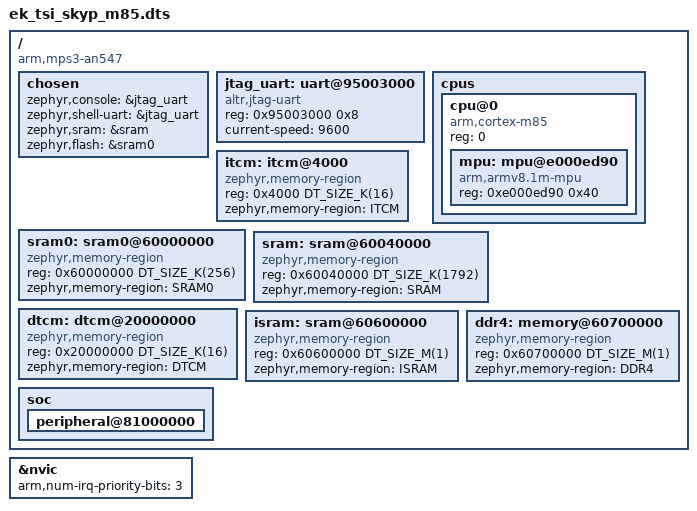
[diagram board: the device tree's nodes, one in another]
/*
 * Copyright (c) 2024 TSI
 * Copyright 2022 Arm Limited and/or its affiliates <open-source-office@arm.com>
 *
 * SPDX-License-Identifier: Apache-2.0
 */

/dts-v1/;

#include <arm/armv8.1-m.dtsi>
#include <zephyr/dt-bindings/i2c/i2c.h>
#include <zephyr/dt-bindings/input/input-event-codes.h>
#include <mem.h>

/ {
	compatible = "arm,mps3-an547";
	#address-cells = <1>;
	#size-cells = <1>;

	chosen {
		zephyr,console = &jtag_uart;
		/*
		zephyr,console = &uart0;
		*/
		zephyr,shell-uart = &jtag_uart;
		/*
		zephyr,shell-uart = &uart0;
		*/
		zephyr,sram = &sram;
		zephyr,flash = &sram0;
	};

        jtag_uart: uart@95003000 {
                compatible = "altr,jtag-uart";
                reg = <0x95003000 0x8>;
                status = "enabled";
        };

	cpus {
		#address-cells = <1>;
		#size-cells = <0>;

		cpu@0 {
			device_type = "cpu";
			compatible = "arm,cortex-m85";
			reg = <0>;
			#address-cells = <1>;
			#size-cells = <1>;

			mpu: mpu@e000ed90 {
				compatible = "arm,armv8.1m-mpu";
				reg = <0xe000ed90 0x40>;
			};
		};
	};

	/* We utilize the secure addresses, if you subtract 0x10000000
	 * you'll get the non-secure alias
	 */
        itcm: itcm@4000 {   /* alias @ 0x4000 */
                compatible = "zephyr,memory-region";
                reg = <0x4000 DT_SIZE_K(16)>;
                zephyr,memory-region = "ITCM";
        };

	sram0: sram0@60000000 {	/* alias @ 0x60000000 */
		compatible = "zephyr,memory-region";
		reg = <0x60000000 DT_SIZE_K(256)>;
		zephyr,memory-region = "SRAM0";
	};

	sram: sram@60040000 {	/* alias @ 0x60040000 */
		compatible = "zephyr,memory-region", "mmio-sram";
		reg = <0x60040000 DT_SIZE_K(1792)>;
		zephyr,memory-region = "SRAM";
	};

	dtcm: dtcm@20000000 {	/* alias @ 0x20000000 */
		compatible = "zephyr,memory-region";
		reg = <0x20000000 DT_SIZE_K(16)>;
		zephyr,memory-region = "DTCM";
	};

	isram: sram@60600000 {/* alias @ 0x60600000 */
		compatible = "zephyr,memory-region", "mmio-sram";
		reg = <0x60600000 DT_SIZE_M(1)>;
		zephyr,memory-region = "ISRAM";
	};

	/* DDR4 - 2G, alternates non-secure/secure every 256M */
	ddr4: memory@60700000 {
		device_type = "memory";
		compatible = "zephyr,memory-region";
		reg = <0x60700000 DT_SIZE_M(1)
		       /*0x70000000 DT_SIZE_M(256)
		       0x80000000 DT_SIZE_M(256)
		       0x90000000 DT_SIZE_M(256)
		       0xa0000000 DT_SIZE_M(256)
		       0xb0000000 DT_SIZE_M(256)
		       0xc0000000 DT_SIZE_M(256)
		       0xd0000000 DT_SIZE_M(256)*/>;
		zephyr,memory-region = "DDR4";
	};

	soc {
		peripheral@81000000 {
			#address-cells = <1>;
			#size-cells = <1>;
			ranges = <0x0 0x81000000 0x1effffff>;

			 #include "ek_tsi_skyp_m85-common.dtsi"
		};
	};
};

&jtag_uart {
	status = "okay";
	current-speed = <9600>;
};

&nvic {
	arm,num-irq-priority-bits = <3>;
};
